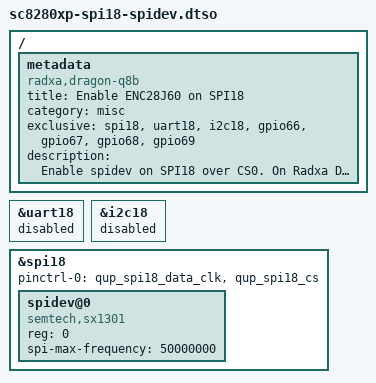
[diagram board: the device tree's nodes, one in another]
// SPDX-License-Identifier: BSD-3-Clause
/*
 * Copyright (c) 2026 Radxa Computer (Shenzhen) Co., Ltd.
 */

/dts-v1/;
/plugin/;

/ {
	metadata {
		title = "Enable ENC28J60 on SPI18";
		compatible = "radxa,dragon-q8b";
		category = "misc";
		exclusive = "spi18", "uart18", "i2c18", "gpio66", "gpio67", "gpio68", "gpio69";
		description = "Enable spidev on SPI18 over CS0.
On Radxa Dragon Q8B, this is pin 13(miso), 15(mosi), 16(sclk), 37(cs0).";
	};
};

&uart18 {
	status = "disabled";
};

&i2c18 {
	status = "disabled";
};

&spi18 {
	pinctrl-0 = <&qup_spi18_data_clk>, <&qup_spi18_cs>;
	pinctrl-names = "default";
	
	status = "okay";
	
	spidev@0 {
		compatible = "semtech,sx1301";
		status = "okay";
		reg = <0>;
		spi-max-frequency = <50000000>;
	};
};
